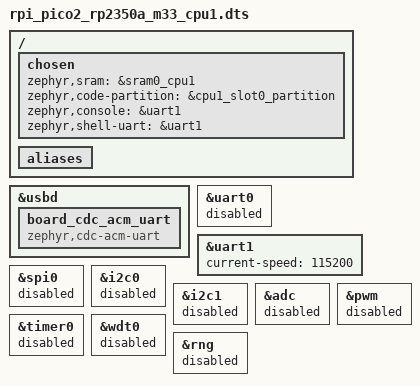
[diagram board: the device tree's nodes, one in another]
/*
 * Copyright (c) 2024 Andrew Featherstone
 *
 * SPDX-License-Identifier: Apache-2.0
 */

/dts-v1/;

/* The build system assumes that there's a cpucluster-specific file.
 *
 * This file provides composition of the devicetree:
 * 1. The common features of the SoC
 * 2. Core-specific configuration.
 * 3. Board-specific configuration.
 */
#include <raspberrypi/rpi_pico/rp2350a.dtsi>
#include <raspberrypi/rpi_pico/m33.dtsi>

/* there's nothing specific to the Cortex-M33 cores vs the (not yet
 * implemented) Hazard3 cores.
 */
#include "rpi_pico2.dtsi"
#include <raspberrypi/rp2350_shared_reserved_memory.dtsi>

/* Include default memory partition configuration file */
#define WITH_CPU1_PARTITIONS
#include <raspberrypi/partitions_4M_default.dtsi>

/ {
	chosen {
		/* Delete CPU0 chosen properties */
		/delete-property/ zephyr,flash;
		/delete-property/ zephyr,flash-controller;

		zephyr,sram = &sram0_cpu1;
		/* Flash is only assigned to CPU0, CPU1 must
		 * execute from RAM to avoid access conflicts
		 * This code parition is only here to set the
		 * correct address for flashing. The code is
		 * moved to and executes from &sram0_cpu1.
		 */
		zephyr,code-partition = &cpu1_slot0_partition;
		// zephyr,console = &board_cdc_acm_uart;
		// zephyr,shell-uart = &board_cdc_acm_uart;
		zephyr,console = &uart1;
		zephyr,shell-uart = &uart1;
	};

	aliases {
		/delete-property/ watchdog0;
	};
};

zephyr_udc0: &usbd {
	status = "okay";
	board_cdc_acm_uart: board_cdc_acm_uart {
		compatible = "zephyr,cdc-acm-uart";
	};
};

&uart0 {
	status = "reserved";
};

&uart1 {
	current-speed = <115200>;
	status = "okay";
};

&spi0 {
	status = "reserved";
};

&i2c0 {
	status = "reserved";
};

&i2c1 {
	status = "reserved";
};

&adc {
	status = "reserved";
};

&pwm {
	status = "reserved";
};

&timer0 {
	status = "reserved";
};

&wdt0 {
	status = "reserved";
};

&rng {
	status = "reserved";
};
